# HDSC_HC32L110 register map
Vendor: HDSC Co.Ltd; Series: ARMCM0P; File version: 1.2
CPU: CM0 r0p0, little endian, no MPU, no FPU, 3 interrupt priority bits
Registers are 32-bit, read-write, reset 0x0 unless marked. A register's access mark holds for its fields unless they carry their own. Offsets are from the block's base; [hi:lo] are bit positions; {n}, {i} and the like mark numbered series.

## GPIO
Base 0x40020C00
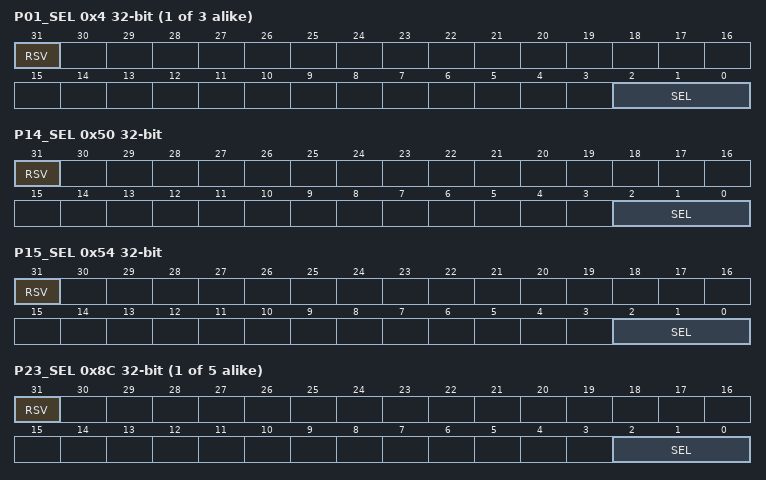
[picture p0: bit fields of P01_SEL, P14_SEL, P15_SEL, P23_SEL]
{0x0+4i} P{i:02}_SEL (reset mask 0x7) (i=1..3)
  [31] RSV, [2:0] SEL
0x50 P14_SEL (reset mask 0x7)
  [31] RSV, [2:0] SEL
0x54 P15_SEL (reset mask 0x7)
  [31] RSV, [2:0] SEL
{0x30+4i} P{i}_SEL (reset mask 0x7) (i=23..27)
  [31] RSV, [2:0] SEL
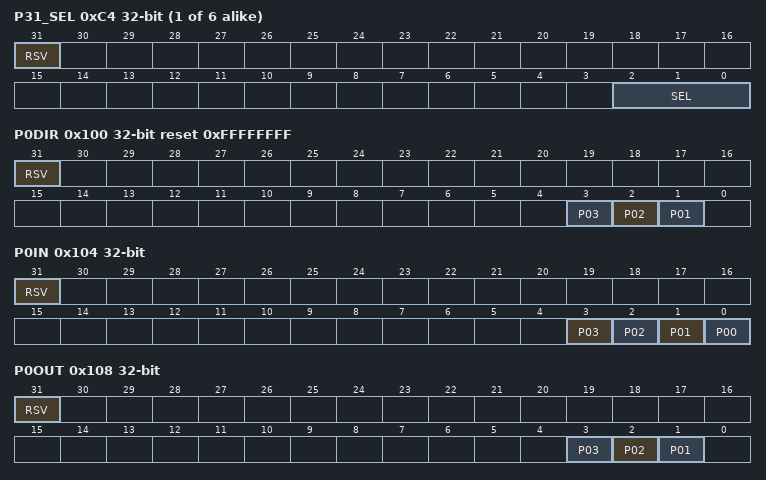
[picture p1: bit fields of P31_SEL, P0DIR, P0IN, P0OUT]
{0x48+4i} P{i}_SEL (reset mask 0x7) (i=31..36)
  [31] RSV, [2:0] SEL
0x100 P0DIR reset 0xFFFFFFFF (reset mask 0xE)
  [31] RSV, [3] P03, [2] P02, [1] P01
0x104 P0IN ro (reset mask 0xF)
  [31] RSV rw, [n] P{n:02} (n=0..3)
0x108 P0OUT (reset mask 0xE)
  [31] RSV, [3] P03, [2] P02, [1] P01
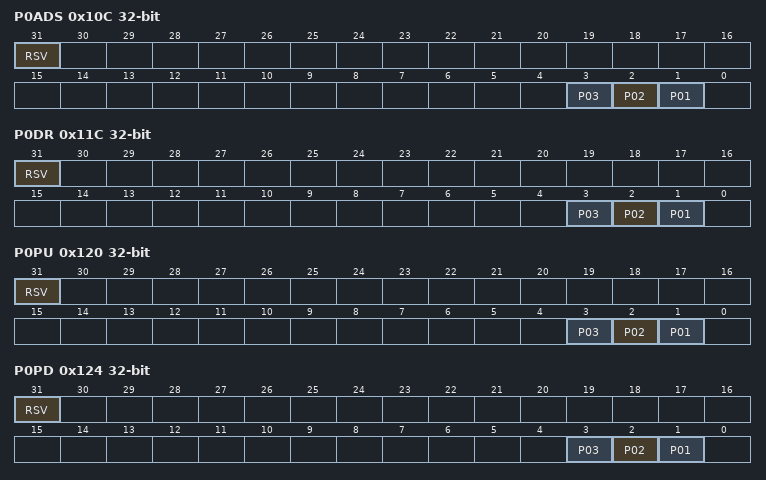
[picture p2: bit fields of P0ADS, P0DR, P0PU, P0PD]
0x10C P0ADS (reset mask 0xE)
  [31] RSV, [3] P03, [2] P02, [1] P01
0x11C P0DR (reset mask 0xE)
  [31] RSV, [3] P03, [2] P02, [1] P01
0x120 P0PU (reset mask 0xE)
  [31] RSV, [3] P03, [2] P02, [1] P01
0x124 P0PD (reset mask 0xE)
  [31] RSV, [3] P03, [2] P02, [1] P01
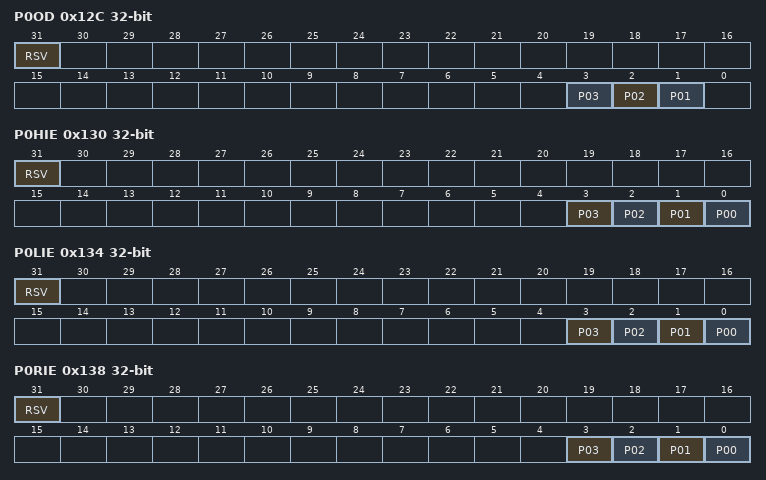
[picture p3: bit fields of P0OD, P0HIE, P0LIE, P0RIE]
0x12C P0OD (reset mask 0xE)
  [31] RSV, [3] P03, [2] P02, [1] P01
0x130 P0HIE ro (reset mask 0xF)
  [31] RSV rw, [n] P{n:02} (n=0..3)
0x134 P0LIE ro (reset mask 0xF)
  [31] RSV rw, [n] P{n:02} (n=0..3)
0x138 P0RIE ro (reset mask 0xF)
  [31] RSV rw, [n] P{n:02} (n=0..3)
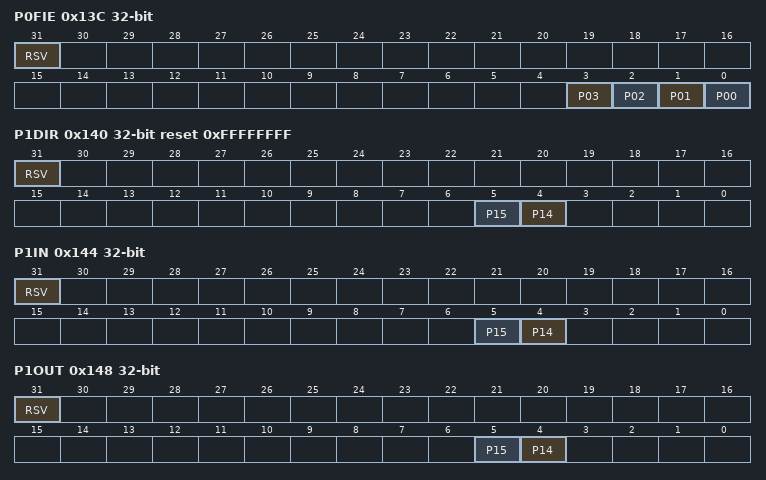
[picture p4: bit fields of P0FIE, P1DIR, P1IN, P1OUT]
0x13C P0FIE ro (reset mask 0xF)
  [31] RSV rw, [n] P{n:02} (n=0..3)
0x140 P1DIR reset 0xFFFFFFFF (reset mask 0x30)
  [31] RSV, [5] P15, [4] P14
0x144 P1IN ro (reset mask 0x3)
  [31] RSV rw, [5] P15, [4] P14
0x148 P1OUT (reset mask 0x30)
  [31] RSV, [5] P15, [4] P14
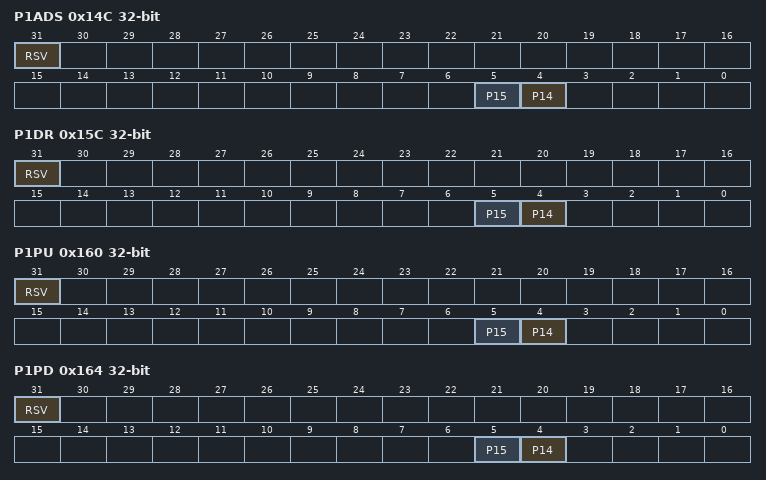
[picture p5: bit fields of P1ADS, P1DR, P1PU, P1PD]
0x14C P1ADS (reset mask 0x30)
  [31] RSV, [5] P15, [4] P14
0x15C P1DR (reset mask 0x30)
  [31] RSV, [5] P15, [4] P14
0x160 P1PU (reset mask 0x30)
  [31] RSV, [5] P15, [4] P14
0x164 P1PD (reset mask 0x30)
  [31] RSV, [5] P15, [4] P14
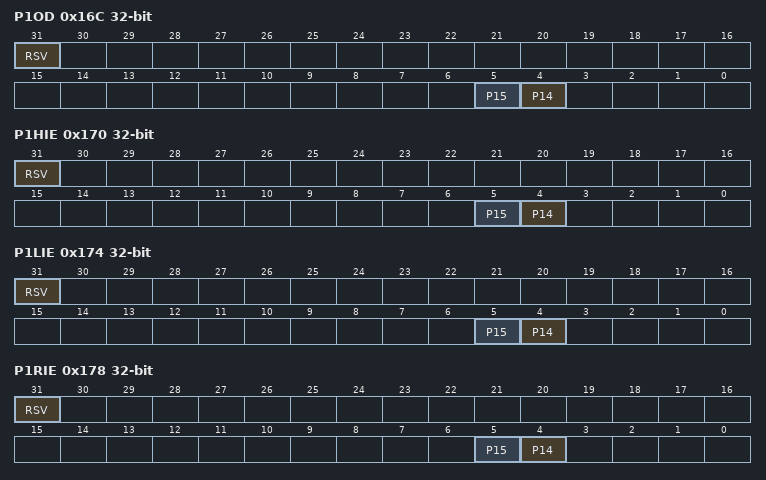
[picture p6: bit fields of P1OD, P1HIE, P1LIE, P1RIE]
0x16C P1OD (reset mask 0x30)
  [31] RSV, [5] P15, [4] P14
0x170 P1HIE ro (reset mask 0x3)
  [31] RSV rw, [5] P15, [4] P14
0x174 P1LIE ro (reset mask 0x3)
  [31] RSV rw, [5] P15, [4] P14
0x178 P1RIE ro (reset mask 0x3)
  [31] RSV rw, [5] P15, [4] P14
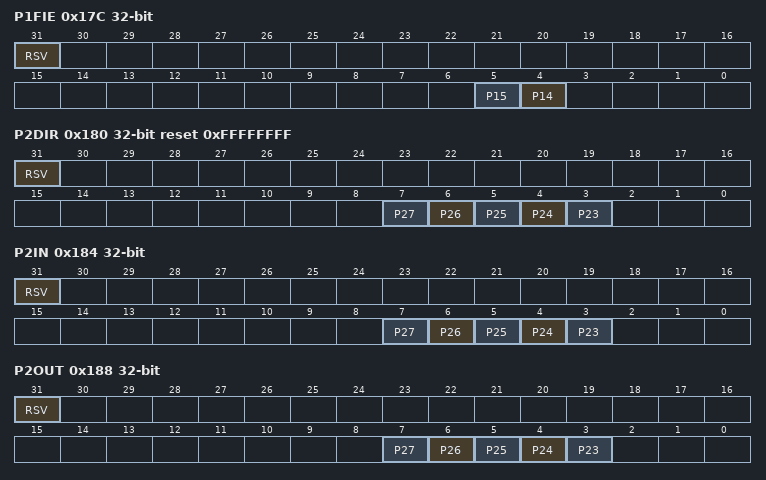
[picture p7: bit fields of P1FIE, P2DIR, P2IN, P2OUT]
0x17C P1FIE ro (reset mask 0x3)
  [31] RSV rw, [5] P15, [4] P14
0x180 P2DIR reset 0xFFFFFFFF (reset mask 0xF8)
  [31] RSV, [n-20] P{n} (n=23..27)
0x184 P2IN ro (reset mask 0x3)
  [31] RSV rw, [n-20] P{n} (n=23..27)
0x188 P2OUT (reset mask 0xF8)
  [31] RSV, [n-20] P{n} (n=23..27)
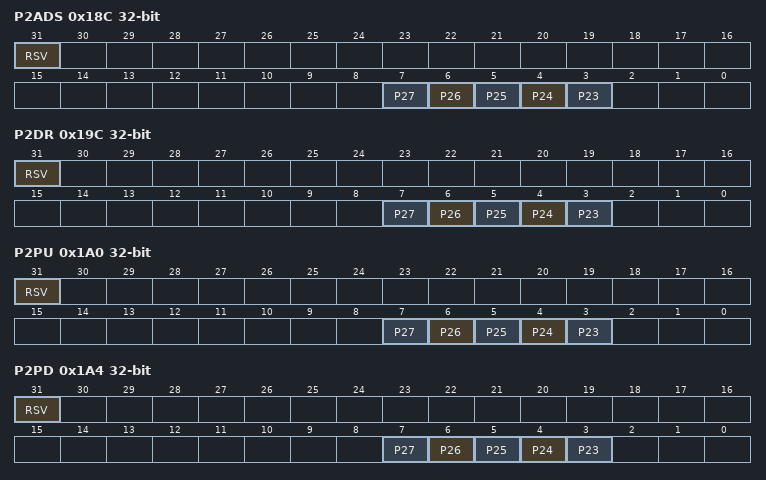
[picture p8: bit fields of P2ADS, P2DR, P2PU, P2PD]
0x18C P2ADS (reset mask 0xF8)
  [31] RSV, [n-20] P{n} (n=23..27)
0x19C P2DR (reset mask 0xF8)
  [31] RSV, [n-20] P{n} (n=23..27)
0x1A0 P2PU (reset mask 0xF8)
  [31] RSV, [n-20] P{n} (n=23..27)
0x1A4 P2PD (reset mask 0xF8)
  [31] RSV, [n-20] P{n} (n=23..27)
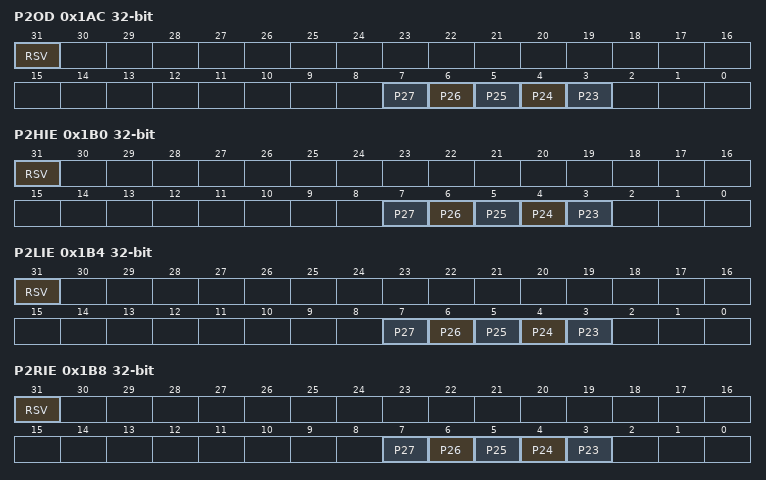
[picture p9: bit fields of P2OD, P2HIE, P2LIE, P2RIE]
0x1AC P2OD (reset mask 0xF8)
  [31] RSV, [n-20] P{n} (n=23..27)
0x1B0 P2HIE ro (reset mask 0x3)
  [31] RSV rw, [n-20] P{n} (n=23..27)
0x1B4 P2LIE ro (reset mask 0x3)
  [31] RSV rw, [n-20] P{n} (n=23..27)
0x1B8 P2RIE ro (reset mask 0x3)
  [31] RSV rw, [n-20] P{n} (n=23..27)
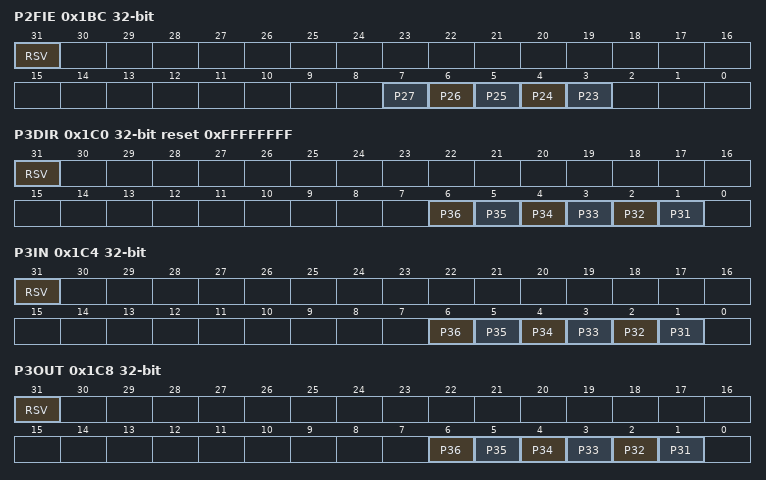
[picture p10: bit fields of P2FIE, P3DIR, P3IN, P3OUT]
0x1BC P2FIE ro (reset mask 0x3)
  [31] RSV rw, [n-20] P{n} (n=23..27)
0x1C0 P3DIR reset 0xFFFFFFFF (reset mask 0x7E)
  [31] RSV, [n-30] P{n} (n=31..36)
0x1C4 P3IN ro (reset mask 0x7E)
  [31] RSV rw, [n-30] P{n} (n=31..36)
0x1C8 P3OUT (reset mask 0x7E)
  [31] RSV, [n-30] P{n} (n=31..36)
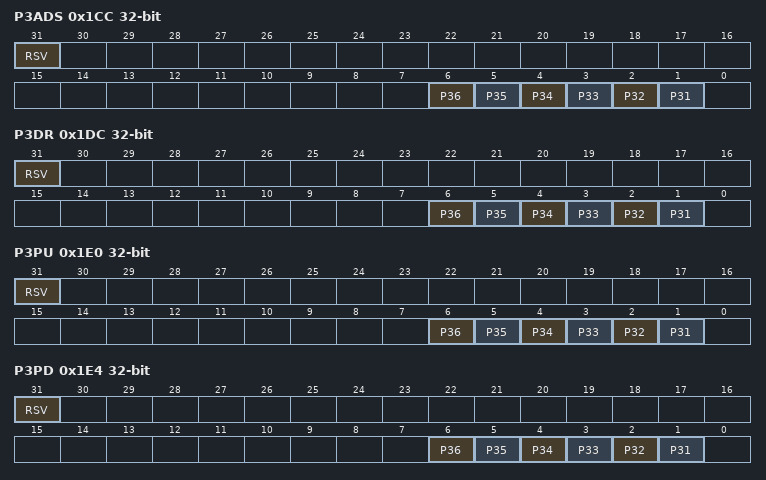
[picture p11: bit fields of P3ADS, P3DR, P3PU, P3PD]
0x1CC P3ADS (reset mask 0x7E)
  [31] RSV, [n-30] P{n} (n=31..36)
0x1DC P3DR (reset mask 0x7E)
  [31] RSV, [n-30] P{n} (n=31..36)
0x1E0 P3PU (reset mask 0x7E)
  [31] RSV, [n-30] P{n} (n=31..36)
0x1E4 P3PD (reset mask 0x7E)
  [31] RSV, [n-30] P{n} (n=31..36)
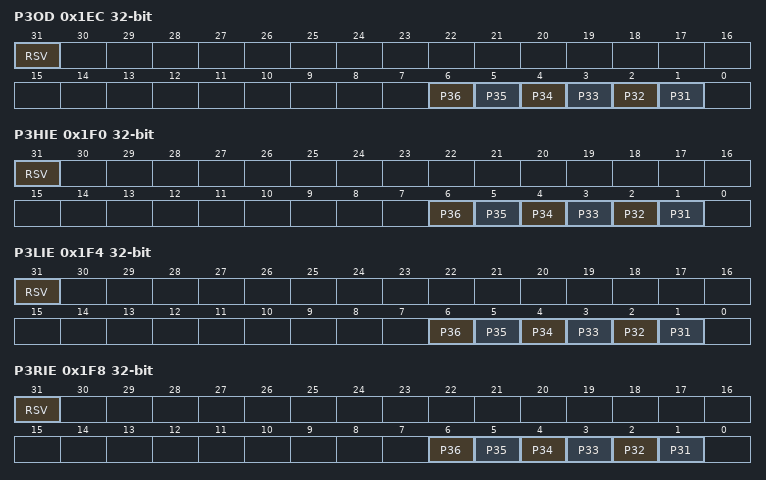
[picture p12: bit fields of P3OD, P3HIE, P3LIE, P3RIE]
0x1EC P3OD (reset mask 0x7E)
  [31] RSV, [n-30] P{n} (n=31..36)
0x1F0 P3HIE ro (reset mask 0x7E)
  [31] RSV rw, [n-30] P{n} (n=31..36)
0x1F4 P3LIE ro (reset mask 0x7E)
  [31] RSV rw, [n-30] P{n} (n=31..36)
0x1F8 P3RIE ro (reset mask 0x7E)
  [31] RSV rw, [n-30] P{n} (n=31..36)
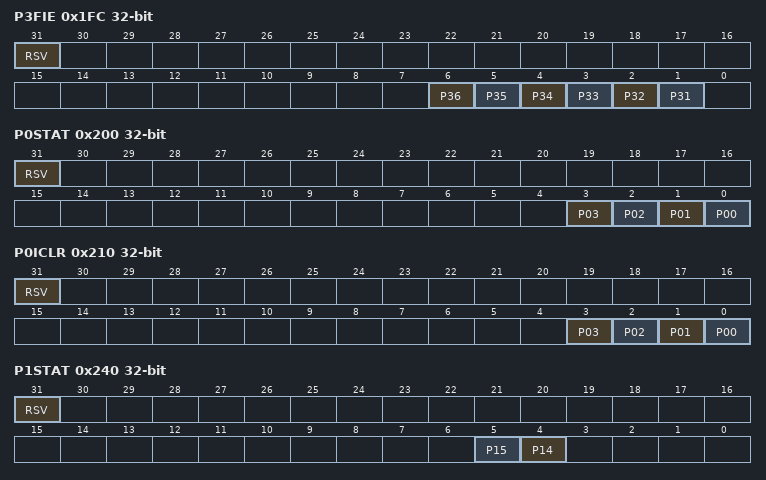
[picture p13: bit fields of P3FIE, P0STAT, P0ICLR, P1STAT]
0x1FC P3FIE ro (reset mask 0x7E)
  [31] RSV rw, [n-30] P{n} (n=31..36)
0x200 P0STAT ro (reset mask 0xF)
  [31] RSV rw, [n] P{n:02} (n=0..3)
0x210 P0ICLR ro (reset mask 0xF)
  [31] RSV rw, [n] P{n:02} (n=0..3)
0x240 P1STAT ro (reset mask 0x3)
  [31] RSV rw, [5] P15, [4] P14
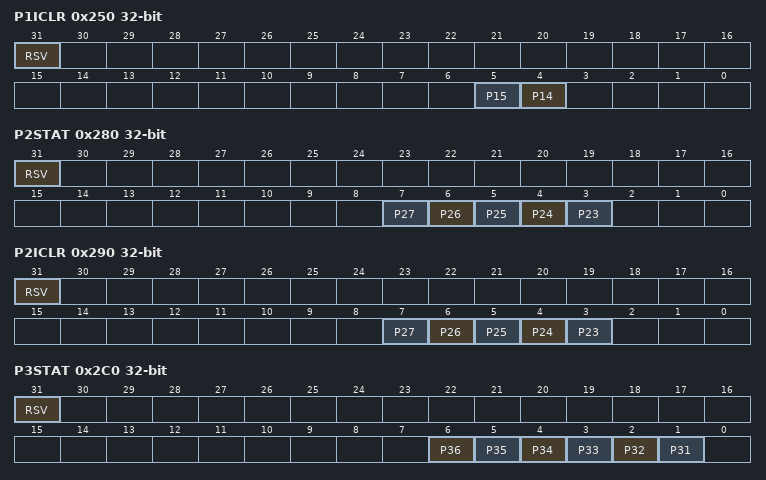
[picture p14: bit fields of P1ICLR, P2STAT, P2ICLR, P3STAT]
0x250 P1ICLR ro (reset mask 0x3)
  [31] RSV rw, [5] P15, [4] P14
0x280 P2STAT ro (reset mask 0x3)
  [31] RSV rw, [n-20] P{n} (n=23..27)
0x290 P2ICLR ro (reset mask 0x3)
  [31] RSV rw, [n-20] P{n} (n=23..27)
0x2C0 P3STAT ro (reset mask 0x7E)
  [31] RSV rw, [n-30] P{n} (n=31..36)
0x2D0 P3ICLR ro (reset mask 0x7E)
  [31] RSV rw, [n-30] P{n} (n=31..36)
0x304 CTRL1 (reset mask 0xFFFF)
  [31] RSV, [14] IR_POL, [13] HCLK_EN, [12] PCLK_EN, [11:10] HCLK_SEL, [9:8] PCLK_SEL, [7:4] SSN_SEL, [3:0] EXT_CLK_SEL
0x308 CTRL2 (reset mask 0x3FF)
  [31] RSV, [2n+1:2n] PCA_CAP{n}_SEL (n=0..4)
0x30C CTRL3 (reset mask 0xFFF)
  [31] RSV, [11:10] TM6_A_SEL, [9:8] TM5_A_SEL, [7:6] TM4_A_SEL, [5:4] TM6_B_SEL, [3:2] TM5_B_SEL, [1:0] TM4_B_SEL
0x310 CTRL4 (reset mask 0xFF)
  [31] RSV, [2n+1:2n] TM{n}_GATE_SEL (n=0..3)
